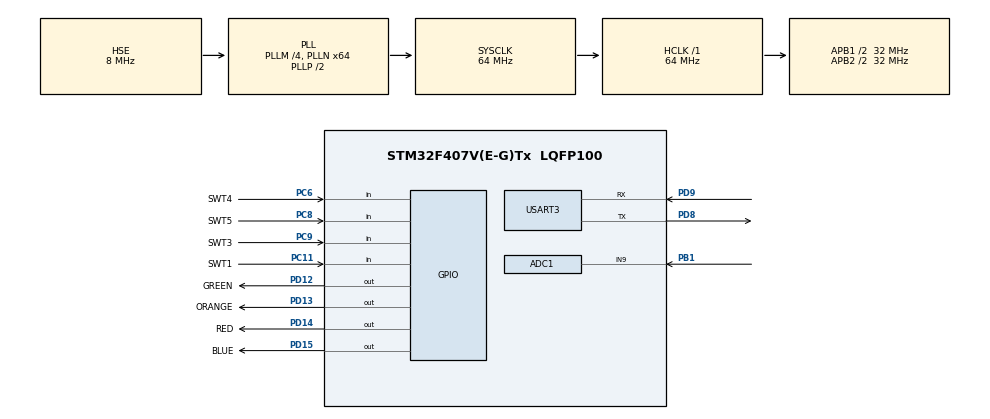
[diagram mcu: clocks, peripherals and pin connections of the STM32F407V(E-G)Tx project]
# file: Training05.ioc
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ADC1.Channel-0\#ChannelRegularConversion=ADC_CHANNEL_9
ADC1.ClockPrescaler=ADC_CLOCK_SYNC_PCLK_DIV8
ADC1.ContinuousConvMode=ENABLE
ADC1.DMAContinuousRequests=ENABLE
ADC1.ExternalTrigConv=ADC_SOFTWARE_START
ADC1.NbrOfConversionFlag=1
ADC1.Rank-0\#ChannelRegularConversion=1
ADC1.SamplingTime-0\#ChannelRegularConversion=ADC_SAMPLETIME_480CYCLES
ADC1.master=1
Dma.ADC1.0.Direction=DMA_PERIPH_TO_MEMORY
Dma.ADC1.0.FIFOMode=DMA_FIFOMODE_ENABLE
Dma.ADC1.0.FIFOThreshold=DMA_FIFO_THRESHOLD_HALFFULL
Dma.ADC1.0.Instance=DMA2_Stream0
Dma.ADC1.0.MemBurst=DMA_MBURST_SINGLE
Dma.ADC1.0.MemDataAlignment=DMA_MDATAALIGN_HALFWORD
Dma.ADC1.0.MemInc=DMA_MINC_ENABLE
Dma.ADC1.0.Mode=DMA_CIRCULAR
Dma.ADC1.0.PeriphBurst=DMA_PBURST_SINGLE
Dma.ADC1.0.PeriphDataAlignment=DMA_PDATAALIGN_HALFWORD
Dma.ADC1.0.PeriphInc=DMA_PINC_DISABLE
Dma.ADC1.0.Priority=DMA_PRIORITY_LOW
Dma.Request0=ADC1
Mcu.Family=STM32F4
Mcu.Name=STM32F407V(E-G)Tx
Mcu.Package=LQFP100
NVIC.DMA2_Stream0_IRQn=true\:0\:0\:false\:false\:true\:false\:true\:true
NVIC.PriorityGroup=NVIC_PRIORITYGROUP_4
PB1.Signal=ADCx_IN9
PC11.GPIO_Label=SWT1
PC11.GPIO_Mode=GPIO_MODE_INPUT
PC11.GPIO_PuPd=GPIO_PULLUP
PC11.Signal=GPIO_Input
PC6.GPIO_Label=SWT4
PC6.GPIO_Mode=GPIO_MODE_INPUT
PC6.GPIO_PuPd=GPIO_PULLUP
PC6.Signal=GPIO_Input
PC8.GPIO_Label=SWT5
PC8.GPIO_PuPd=GPIO_PULLUP
PC8.Signal=GPIO_Input
PC9.GPIO_Label=SWT3
PC9.GPIO_Mode=GPIO_MODE_INPUT
PC9.GPIO_PuPd=GPIO_PULLUP
PC9.Signal=GPIO_Input
PD12.GPIO_Label=GREEN
PD12.GPIO_ModeDefaultOutputPP=GPIO_MODE_OUTPUT_PP
PD12.GPIO_Speed=GPIO_SPEED_FREQ_LOW
PD12.Signal=GPIO_Output
PD13.GPIO_Label=ORANGE
PD13.GPIO_ModeDefaultOutputPP=GPIO_MODE_OUTPUT_PP
PD13.GPIO_Speed=GPIO_SPEED_FREQ_LOW
PD13.Signal=GPIO_Output
PD14.GPIO_Label=RED
PD14.GPIO_ModeDefaultOutputPP=GPIO_MODE_OUTPUT_PP
PD14.GPIO_Speed=GPIO_SPEED_FREQ_LOW
PD14.Signal=GPIO_Output
PD15.GPIO_Label=BLUE
PD15.GPIO_ModeDefaultOutputPP=GPIO_MODE_OUTPUT_PP
PD15.GPIO_Speed=GPIO_SPEED_FREQ_LOW
PD15.Signal=GPIO_Output
PD8.Mode=Asynchronous
PD8.Signal=USART3_TX
PD9.Mode=Asynchronous
PD9.Signal=USART3_RX
PH0-OSC_IN.Mode=HSE-External-Oscillator
PH0-OSC_IN.Signal=RCC_OSC_IN
PH1-OSC_OUT.Mode=HSE-External-Oscillator
PH1-OSC_OUT.Signal=RCC_OSC_OUT
ProjectManager.HeapSize=0x200
ProjectManager.StackSize=0x400
ProjectManager.TargetToolchain=STM32CubeIDE
RCC.48MHZClocksFreq_Value=32000000
RCC.AHBFreq_Value=64000000
RCC.APB1CLKDivider=RCC_HCLK_DIV2
RCC.APB1Freq_Value=32000000
RCC.APB1TimFreq_Value=64000000
RCC.APB2CLKDivider=RCC_HCLK_DIV2
RCC.APB2Freq_Value=32000000
RCC.APB2TimFreq_Value=64000000
RCC.CortexFreq_Value=64000000
RCC.HCLKFreq_Value=64000000
RCC.HSE_VALUE=8000000
RCC.HSI_VALUE=16000000
RCC.LSE_VALUE=32768
RCC.PLLM=4
RCC.PLLN=64
RCC.PLLSourceVirtual=RCC_PLLSOURCE_HSE
RCC.SYSCLKFreq_VALUE=64000000
RCC.SYSCLKSource=RCC_SYSCLKSOURCE_PLLCLK
RCC.VCOOutputFreq_Value=128000000
SH.ADCx_IN9.0=ADC1_IN9,IN9
USART3.VirtualMode=VM_ASYNC
board=custom

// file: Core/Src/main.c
/* USER CODE BEGIN Header */
/**
  ******************************************************************************
  * @file           : main.c
  * @brief          : Main program body
  ******************************************************************************
  * @attention
  *
  * Copyright (c) 2023 STMicroelectronics.
  * All rights reserved.
  *
  * This software is licensed under terms that can be found in the LICENSE file
  * in the root directory of this software component.
  * If no LICENSE file comes with this software, it is provided AS-IS.
  *
  ******************************************************************************
  */
/* USER CODE END Header */
#include "main.h"

ADC_HandleTypeDef hadc1;
DMA_HandleTypeDef hdma_adc1;

UART_HandleTypeDef huart3;

void SystemClock_Config(void);
static void MX_GPIO_Init(void);
static void MX_DMA_Init(void);
static void MX_USART3_UART_Init(void);
static void MX_ADC1_Init(void);

int main(void)
{

  /* MCU Configuration--------------------------------------------------------*/

  /* Reset of all peripherals, Initializes the Flash interface and the Systick. */
  HAL_Init();

  /* Configure the system clock */
  SystemClock_Config();

  /* Initialize all configured peripherals */
  MX_GPIO_Init();
  MX_DMA_Init();
  MX_USART3_UART_Init();
  MX_ADC1_Init();

  /* Infinite loop */
  /* USER CODE BEGIN WHILE */

  while (1)
  {
	  PollUart();
	  PollButtons();
	  HandleExtTempChannel();

    /* USER CODE END WHILE */

  }
}

void SystemClock_Config(void)
{
  RCC_OscInitTypeDef RCC_OscInitStruct = {0};
  RCC_ClkInitTypeDef RCC_ClkInitStruct = {0};

  /** Configure the main internal regulator output voltage
  */
  __HAL_RCC_PWR_CLK_ENABLE();
  __HAL_PWR_VOLTAGESCALING_CONFIG(PWR_REGULATOR_VOLTAGE_SCALE1);

  /** Initializes the RCC Oscillators according to the specified parameters
  * in the RCC_OscInitTypeDef structure.
  */
  RCC_OscInitStruct.OscillatorType = RCC_OSCILLATORTYPE_HSE;
  RCC_OscInitStruct.HSEState = RCC_HSE_ON;
  RCC_OscInitStruct.PLL.PLLState = RCC_PLL_ON;
  RCC_OscInitStruct.PLL.PLLSource = RCC_PLLSOURCE_HSE;
  RCC_OscInitStruct.PLL.PLLM = 4;
  RCC_OscInitStruct.PLL.PLLN = 64;
  RCC_OscInitStruct.PLL.PLLP = RCC_PLLP_DIV2;
  RCC_OscInitStruct.PLL.PLLQ = 4;
  if (HAL_RCC_OscConfig(&RCC_OscInitStruct) != HAL_OK)
  {
    Error_Handler();
  }

  /** Initializes the CPU, AHB and APB buses clocks
  */
  RCC_ClkInitStruct.ClockType = RCC_CLOCKTYPE_HCLK|RCC_CLOCKTYPE_SYSCLK
                              |RCC_CLOCKTYPE_PCLK1|RCC_CLOCKTYPE_PCLK2;
  RCC_ClkInitStruct.SYSCLKSource = RCC_SYSCLKSOURCE_PLLCLK;
  RCC_ClkInitStruct.AHBCLKDivider = RCC_SYSCLK_DIV1;
  RCC_ClkInitStruct.APB1CLKDivider = RCC_HCLK_DIV2;
  RCC_ClkInitStruct.APB2CLKDivider = RCC_HCLK_DIV2;

  if (HAL_RCC_ClockConfig(&RCC_ClkInitStruct, FLASH_LATENCY_2) != HAL_OK)
  {
    Error_Handler();
  }
}

static void MX_ADC1_Init(void)
{

  ADC_ChannelConfTypeDef sConfig = {0};

  /** Configure the global features of the ADC (Clock, Resolution, Data Alignment and number of conversion)
  */
  hadc1.Instance = ADC1;
  hadc1.Init.ClockPrescaler = ADC_CLOCK_SYNC_PCLK_DIV8;
  hadc1.Init.Resolution = ADC_RESOLUTION_12B;
  hadc1.Init.ScanConvMode = DISABLE;
  hadc1.Init.ContinuousConvMode = ENABLE;
  hadc1.Init.DiscontinuousConvMode = DISABLE;
  hadc1.Init.ExternalTrigConvEdge = ADC_EXTERNALTRIGCONVEDGE_NONE;
  hadc1.Init.ExternalTrigConv = ADC_SOFTWARE_START;
  hadc1.Init.DataAlign = ADC_DATAALIGN_RIGHT;
  hadc1.Init.NbrOfConversion = 1;
  hadc1.Init.DMAContinuousRequests = ENABLE;
  hadc1.Init.EOCSelection = ADC_EOC_SINGLE_CONV;
  if (HAL_ADC_Init(&hadc1) != HAL_OK)
  {
    Error_Handler();
  }

  /** Configure for the selected ADC regular channel its corresponding rank in the sequencer and its sample time.
  */
  sConfig.Channel = ADC_CHANNEL_9;
  sConfig.Rank = 1;
  sConfig.SamplingTime = ADC_SAMPLETIME_480CYCLES;
  if (HAL_ADC_ConfigChannel(&hadc1, &sConfig) != HAL_OK)
  {
    Error_Handler();
  }

}

static void MX_USART3_UART_Init(void)
{

  huart3.Instance = USART3;
  huart3.Init.BaudRate = 115200;
  huart3.Init.WordLength = UART_WORDLENGTH_8B;
  huart3.Init.StopBits = UART_STOPBITS_1;
  huart3.Init.Parity = UART_PARITY_NONE;
  huart3.Init.Mode = UART_MODE_TX_RX;
  huart3.Init.HwFlowCtl = UART_HWCONTROL_NONE;
  huart3.Init.OverSampling = UART_OVERSAMPLING_16;
  if (HAL_UART_Init(&huart3) != HAL_OK)
  {
    Error_Handler();
  }

}

static void MX_DMA_Init(void)
{

  /* DMA controller clock enable */
  __HAL_RCC_DMA2_CLK_ENABLE();

  /* DMA interrupt init */
  /* DMA2_Stream0_IRQn interrupt configuration */
  HAL_NVIC_SetPriority(DMA2_Stream0_IRQn, 0, 0);
  HAL_NVIC_EnableIRQ(DMA2_Stream0_IRQn);

}

static void MX_GPIO_Init(void)
{
  GPIO_InitTypeDef GPIO_InitStruct = {0};

  /* GPIO Ports Clock Enable */
  __HAL_RCC_GPIOH_CLK_ENABLE();
  __HAL_RCC_GPIOB_CLK_ENABLE();
  __HAL_RCC_GPIOD_CLK_ENABLE();
  __HAL_RCC_GPIOC_CLK_ENABLE();

  /*Configure GPIO pin Output Level */
  HAL_GPIO_WritePin(GPIOD, GREEN_Pin|ORANGE_Pin|RED_Pin|BLUE_Pin, GPIO_PIN_RESET);

  /*Configure GPIO pins : GREEN_Pin ORANGE_Pin RED_Pin BLUE_Pin */
  GPIO_InitStruct.Pin = GREEN_Pin|ORANGE_Pin|RED_Pin|BLUE_Pin;
  GPIO_InitStruct.Mode = GPIO_MODE_OUTPUT_PP;
  GPIO_InitStruct.Pull = GPIO_NOPULL;
  GPIO_InitStruct.Speed = GPIO_SPEED_FREQ_LOW;
  HAL_GPIO_Init(GPIOD, &GPIO_InitStruct);

  /*Configure GPIO pins : SWT4_Pin SWT5_Pin SWT3_Pin SWT1_Pin */
  GPIO_InitStruct.Pin = SWT4_Pin|SWT5_Pin|SWT3_Pin|SWT1_Pin;
  GPIO_InitStruct.Mode = GPIO_MODE_INPUT;
  GPIO_InitStruct.Pull = GPIO_PULLUP;
  HAL_GPIO_Init(GPIOC, &GPIO_InitStruct);

}

void Error_Handler(void)
{
  __disable_irq();
  while (1)
  {
  }
}
